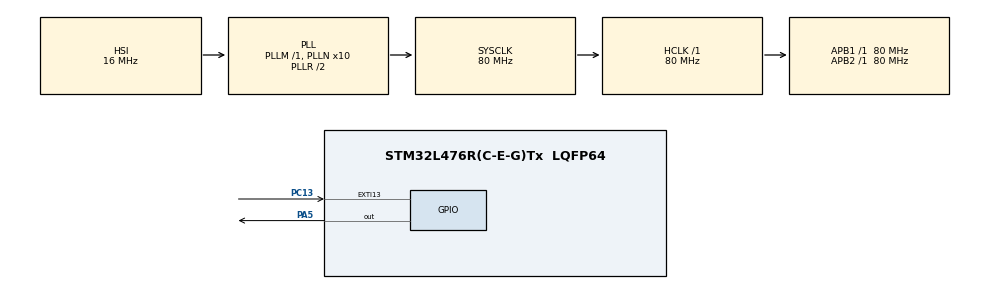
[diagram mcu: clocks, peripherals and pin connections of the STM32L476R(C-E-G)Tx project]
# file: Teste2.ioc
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Mcu.Family=STM32L4
Mcu.Name=STM32L476R(C-E-G)Tx
Mcu.Package=LQFP64
NUCLEO-L476RG.BUTTON=1
NUCLEO-L476RG.LD2=true
NVIC.EXTI15_10_IRQn=true\:0\:0\:false\:false\:true\:false\:true\:true
NVIC.PriorityGroup=NVIC_PRIORITYGROUP_4
PA13\ (JTMS-SWDIO).GPIO_Label=TMS
PA13\ (JTMS-SWDIO).Signal=SYS_JTMS-SWDIO
PA14\ (JTCK-SWCLK).GPIO_Label=TCK
PA14\ (JTCK-SWCLK).Signal=SYS_JTCK-SWCLK
PA2.GPIO_Label=USART_TX
PA2.GPIO_Mode=GPIO_MODE_AF_PP
PA2.GPIO_PuPd=GPIO_NOPULL
PA2.GPIO_Speed=GPIO_SPEED_FREQ_VERY_HIGH
PA2.Signal=USART2_TX
PA3.GPIO_Label=USART_RX
PA3.GPIO_Mode=GPIO_MODE_AF_PP
PA3.GPIO_PuPd=GPIO_NOPULL
PA3.GPIO_Speed=GPIO_SPEED_FREQ_VERY_HIGH
PA3.Signal=USART2_RX
PA5.GPIO_Speed=GPIO_SPEED_FREQ_VERY_HIGH
PA5.PinState=GPIO_PIN_RESET
PA5.Signal=GPIO_Output
PB3\ (JTDO-TRACESWO).GPIO_Label=SWO
PB3\ (JTDO-TRACESWO).Signal=SYS_JTDO-SWO
PC13.Signal=GPXTI13
PC14-OSC32_IN\ (PC14).Signal=RCC_OSC32_IN
PC15-OSC32_OUT\ (PC15).Signal=RCC_OSC32_OUT
PH0-OSC_IN\ (PH0).Signal=RCC_OSC_IN
PH1-OSC_OUT\ (PH1).Signal=RCC_OSC_OUT
ProjectManager.HeapSize=0x200
ProjectManager.StackSize=0x400
ProjectManager.TargetToolchain=STM32CubeIDE
RCC.ADCFreq_Value=64000000
RCC.AHBFreq_Value=80000000
RCC.APB1Freq_Value=80000000
RCC.APB1TimFreq_Value=80000000
RCC.APB2Freq_Value=80000000
RCC.APB2TimFreq_Value=80000000
RCC.CortexFreq_Value=80000000
RCC.HCLKFreq_Value=80000000
RCC.HSE_VALUE=8000000
RCC.HSI_VALUE=16000000
RCC.LSE_VALUE=32768
RCC.MSI_VALUE=4000000
RCC.PLLN=10
RCC.PLLSourceVirtual=RCC_PLLSOURCE_HSI
RCC.PREFETCH_ENABLE=1
RCC.SYSCLKFreq_VALUE=80000000
RCC.SYSCLKSource=RCC_SYSCLKSOURCE_PLLCLK
RCC.USBFreq_Value=64000000
RCC.VCOOutputFreq_Value=160000000
VP_NUCLEO-L476RG_VS_BSP_COMMON.Mode=COMMON
board=NUCLEO-L476RG

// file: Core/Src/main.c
/* USER CODE BEGIN Header */
/**
  ******************************************************************************
  * @file           : main.c
  * @brief          : Main program body
  ******************************************************************************
  */
/* USER CODE END Header */

#include "main.h"
#include <stdio.h>

/* USER CODE BEGIN PV */

/* frequência atual */
volatile uint16_t current_frequency = 60;

/* ponteiro que aponta para current_frequency */
volatile uint16_t *pointer_current_frequency = &current_frequency;

/* USER CODE END PV */

void SystemClock_Config(void);
static void MX_GPIO_Init(void);

/* USER CODE BEGIN PFP */

void software_pwm(uint16_t frequency, uint8_t duty_cycle);

/* USER CODE END PFP */

/* USER CODE BEGIN 0 */

void software_pwm(uint16_t frequency, uint8_t duty_cycle)
{
    uint32_t period_ms;
    uint32_t on_time;
    uint32_t off_time;

    /* calcula período em milissegundos */
    period_ms = 1000 / frequency;

    /* calcula tempos ligado e desligado */
    on_time = (period_ms * duty_cycle) / 100;
    off_time = period_ms - on_time;

    /* liga LED */
    HAL_GPIO_WritePin(GPIOA, GPIO_PIN_5, GPIO_PIN_SET);

    HAL_Delay(on_time);

    /* desliga LED */
    HAL_GPIO_WritePin(GPIOA, GPIO_PIN_5, GPIO_PIN_RESET);

    HAL_Delay(off_time);
}

/* USER CODE END 0 */

int main(void)
{

    /* MCU Configuration--------------------------------------------------------*/

    HAL_Init();

    SystemClock_Config();

    /* Initialize all configured peripherals */

    MX_GPIO_Init();

    /* USER CODE BEGIN 2 */

    /*
     * Inicializa o botão azul no modo de interrupção.
     */
    BSP_PB_Init(BUTTON_USER, BUTTON_MODE_EXTI);

    /* USER CODE END 2 */

    /* Infinite loop */

    while (1)
    {

        /* USER CODE BEGIN 3 */

        /*
         * O ponteiro contém o endereço de current_frequency.
         *
         * *pointer_current_frequency acessa o valor armazenado
         * nesse endereço.
         */
        software_pwm(*pointer_current_frequency, 50);

        /* USER CODE END 3 */
    }
}

void SystemClock_Config(void)
{
    RCC_OscInitTypeDef RCC_OscInitStruct = {0};
    RCC_ClkInitTypeDef RCC_ClkInitStruct = {0};

    /*
     * Configure the main internal regulator output voltage
     */

    if (HAL_PWREx_ControlVoltageScaling(
            PWR_REGULATOR_VOLTAGE_SCALE1) != HAL_OK)
    {
        Error_Handler();
    }

    /*
     * Initializes the RCC Oscillators
     */

    RCC_OscInitStruct.OscillatorType =
        RCC_OSCILLATORTYPE_HSI;

    RCC_OscInitStruct.HSIState =
        RCC_HSI_ON;

    RCC_OscInitStruct.HSICalibrationValue =
        RCC_HSICALIBRATION_DEFAULT;

    RCC_OscInitStruct.PLL.PLLState =
        RCC_PLL_ON;

    RCC_OscInitStruct.PLL.PLLSource =
        RCC_PLLSOURCE_HSI;

    RCC_OscInitStruct.PLL.PLLM = 1;

    RCC_OscInitStruct.PLL.PLLN = 10;

    RCC_OscInitStruct.PLL.PLLP =
        RCC_PLLP_DIV7;

    RCC_OscInitStruct.PLL.PLLQ =
        RCC_PLLQ_DIV2;

    RCC_OscInitStruct.PLL.PLLR =
        RCC_PLLR_DIV2;

    if (HAL_RCC_OscConfig(
            &RCC_OscInitStruct) != HAL_OK)
    {
        Error_Handler();
    }

    /*
     * Initializes the CPU, AHB and APB buses clocks
     */

    RCC_ClkInitStruct.ClockType =
        RCC_CLOCKTYPE_HCLK |
        RCC_CLOCKTYPE_SYSCLK |
        RCC_CLOCKTYPE_PCLK1 |
        RCC_CLOCKTYPE_PCLK2;

    RCC_ClkInitStruct.SYSCLKSource =
        RCC_SYSCLKSOURCE_PLLCLK;

    RCC_ClkInitStruct.AHBCLKDivider =
        RCC_SYSCLK_DIV1;

    RCC_ClkInitStruct.APB1CLKDivider =
        RCC_HCLK_DIV1;

    RCC_ClkInitStruct.APB2CLKDivider =
        RCC_HCLK_DIV1;

    if (HAL_RCC_ClockConfig(
            &RCC_ClkInitStruct,
            FLASH_LATENCY_4) != HAL_OK)
    {
        Error_Handler();
    }
}

static void MX_GPIO_Init(void)
{
    GPIO_InitTypeDef GPIO_InitStruct = {0};

    /* GPIO Ports Clock Enable */

    __HAL_RCC_GPIOC_CLK_ENABLE();
    __HAL_RCC_GPIOH_CLK_ENABLE();
    __HAL_RCC_GPIOA_CLK_ENABLE();
    __HAL_RCC_GPIOB_CLK_ENABLE();

    /* Inicialmente deixa o LED apagado */

    HAL_GPIO_WritePin(
        GPIOA,
        GPIO_PIN_5,
        GPIO_PIN_RESET
    );

    /*
     * Configura PA5 como saída
     */

    GPIO_InitStruct.Pin =
        GPIO_PIN_5;

    GPIO_InitStruct.Mode =
        GPIO_MODE_OUTPUT_PP;

    GPIO_InitStruct.Pull =
        GPIO_NOPULL;

    GPIO_InitStruct.Speed =
        GPIO_SPEED_FREQ_VERY_HIGH;

    HAL_GPIO_Init(
        GPIOA,
        &GPIO_InitStruct
    );
}

/* USER CODE BEGIN 4 */

/*
 * Callback chamada pela HAL quando ocorre
 * uma interrupção externa de GPIO.
 */

void HAL_GPIO_EXTI_Callback(uint16_t GPIO_Pin)
{
    /*
     * Botão azul normalmente está ligado ao PC13.
     */
    if (GPIO_Pin == GPIO_PIN_13)
    {
        /*
         * O ponteiro aponta para current_frequency.
         *
         * Portanto:
         *
         * *pointer_current_frequency
         *
         * equivale a acessar current_frequency.
         */

        if (*pointer_current_frequency == 60)
        {
            /*
             * altera current_frequency para 1
             * usando o ponteiro
             */
            *pointer_current_frequency = 1;
        }
        else
        {
            /*
             * altera current_frequency para 60
             * usando o ponteiro
             */
            *pointer_current_frequency = 60;
        }
    }
    else
    {
        __NOP();
    }
}

/* USER CODE END 4 */

void Error_Handler(void)
{
    __disable_irq();

    while (1)
    {
    }
}
